# STM32F407 register map
File version: 1.2
CPU: CM4 r1p0, little endian, no MPU, no FPU, 4 interrupt priority bits
Registers are 32-bit, read-write, reset 0x0 unless marked. A register's access mark holds for its fields unless they carry their own. Offsets are from the block's base; [hi:lo] are bit positions; {n}, {i} and the like mark numbered series; 'fields as' and 'values as' point back to an identical list.

## FSMC — Flexible static memory controller
Base 0xA0000000
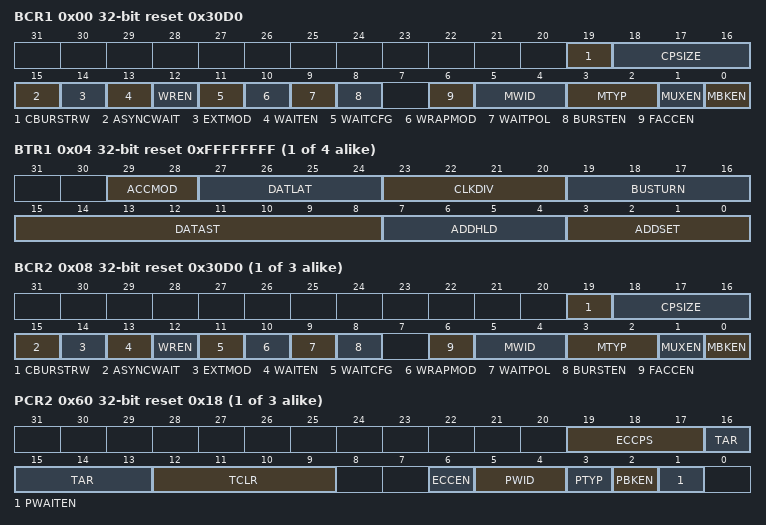
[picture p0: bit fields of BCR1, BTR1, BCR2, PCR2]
0x00 BCR1 reset 0x30D0 — SRAM/NOR-Flash chip-select control register 1
  [19] CBURSTRW
    1=Enabled (Write operations are performed in synchronous mode); 0=Disabled (Write operations are always performed in asynchronous mode)
  [18:16] CPSIZE — CRAM page size
    0=No burst split when crossing page boundary; 1=Bytes128 (128 bytes CRAM page size); 2=Bytes256 (256 bytes CRAM page size); 3=Bytes512 (512 bytes CRAM page size); 4=Bytes1024 (1024 bytes CRAM page size)
  [15] ASYNCWAIT
    0=Disabled (Wait signal not used in asynchronous mode); 1=Enabled (Wait signal used even in asynchronous mode)
  [14] EXTMOD
    0=Disabled (Values inside the FMC_BWTR are not taken into account); 1=Enabled (Values inside the FMC_BWTR are taken into account)
  [13] WAITEN
    0=Disabled (Values inside the FMC_BWTR are taken into account); 1=Enabled (NWAIT signal enabled)
  [12] WREN
    0=Disabled (Write operations disabled for the bank by the FMC); 1=Enabled (Write operations enabled for the bank by the FMC)
  [11] WAITCFG
    0=BeforeWaitState (NWAIT signal is active one data cycle before wait state); 1=DuringWaitState (NWAIT signal is active during wait state)
  [10] WRAPMOD
  [9] WAITPOL
    0=ActiveLow (NWAIT active low); 1=ActiveHigh (NWAIT active high)
  [8] BURSTEN
    0=Disabled (Burst mode disabled); 1=Enabled (Burst mode enabled)
  [6] FACCEN
    0=Disabled (Corresponding NOR Flash memory access is disabled); 1=Enabled (Corresponding NOR Flash memory access is enabled)
  [5:4] MWID
    0=Bits8 (Memory data bus width 8 bits); 1=Bits16 (Memory data bus width 16 bits); 2=Bits32 (Memory data bus width 32 bits)
  [3:2] MTYP
    0=SRAM (SRAM memory type); 1=PSRAM (PSRAM (CRAM) memory type); 2=Flash (NOR Flash/OneNAND Flash)
  [1] MUXEN
    0=Disabled (Address/Data non-multiplexed); 1=Enabled (Address/Data multiplexed on databus)
  [0] MBKEN
    0=Disabled (Corresponding memory bank is disabled); 1=Enabled (Corresponding memory bank is enabled)
0x04 BTR{i} (i=1..4; step 0x8) reset 0xFFFFFFFF — SRAM/NOR-Flash chip-select timing register 1
  [29:28] ACCMOD
    0=A (Access mode A); 1=B (Access mode B); 2=C (Access mode C); 3=D (Access mode D)
  [27:24] DATLAT
  [23:20] CLKDIV range 1..15
  [19:16] BUSTURN
  [15:8] DATAST range 1..255
  [7:4] ADDHLD range 1..15
  [3:0] ADDSET
0x08 BCR{i} (i=2..4; step 0x8) reset 0x30D0 — SRAM/NOR-Flash chip-select control register 2
  fields as BCR1
{0x20+0x20*i} PCR{i} (i=2..4) reset 0x18 — PC Card/NAND Flash control register 2
  [19:17] ECCPS
    0=Bytes256 (ECC page size 256 bytes); 1=Bytes512 (ECC page size 512 bytes); 2=Bytes1024 (ECC page size 1024 bytes); 3=Bytes2048 (ECC page size 2048 bytes); 4=Bytes4096 (ECC page size 4096 bytes); 5=Bytes8192 (ECC page size 8192 bytes)
  [16:13] TAR
  [12:9] TCLR
  [6] ECCEN
    0=Disabled (ECC logic is disabled and reset); 1=Enabled (ECC logic is enabled)
  [5:4] PWID
    0=Bits8 (External memory device width 8 bits); 1=Bits16 (External memory device width 16 bits)
  [3] PTYP
    1=NANDFlash
  [2] PBKEN
    values as BCR1.MBKEN
  [1] PWAITEN
    0=Disabled (Wait feature disabled); 1=Enabled (Wait feature enabled)
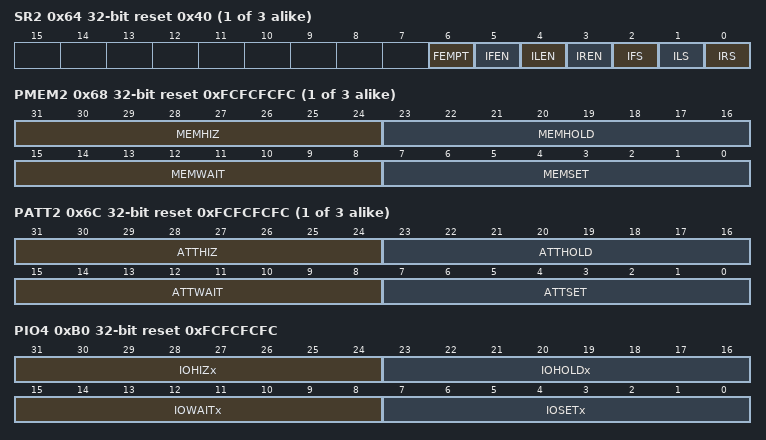
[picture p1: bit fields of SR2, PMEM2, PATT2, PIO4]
{0x24+0x20*i} SR{i} (i=2..4) access per field reset 0x40 — FIFO status and interrupt register 2
  [6] FEMPT ro
    0=NotEmpty (FIFO not empty); 1=Empty (FIFO empty)
  [5] IFEN rw
    0=Disabled (Interrupt falling edge detection request disabled); 1=Enabled (Interrupt falling edge detection request enabled)
  [4] ILEN rw
    0=Disabled (Interrupt high-level detection request disabled); 1=Enabled (Interrupt high-level detection request enabled)
  [3] IREN rw
    0=Disabled (Interrupt rising edge detection request disabled); 1=Enabled (Interrupt rising edge detection request enabled)
  [2] IFS rw
    0=DidNotOccur (Interrupt falling edge did not occur); 1=Occurred (Interrupt falling edge occurred)
  [1] ILS rw
    0=DidNotOccur (Interrupt high-level did not occur); 1=Occurred (Interrupt high-level occurred)
  [0] IRS rw
    0=DidNotOccur (Interrupt rising edge did not occur); 1=Occurred (Interrupt rising edge occurred)
{0x28+0x20*i} PMEM{i} reset 0xFCFCFCFC (i=2..4) — Common memory space timing register {i}
  [31:24] MEMHIZ range 0..254 — MEMHIZx
  [23:16] MEMHOLD range 1..254 — MEMHOLDx
  [15:8] MEMWAIT range 1..254 — MEMWAITx
  [7:0] MEMSET range 0..254 — MEMSETx
{0x2C+0x20*i} PATT{i} reset 0xFCFCFCFC (i=2..4) — Attribute memory space timing register {i}
  [31:24] ATTHIZ range 0..254 — ATTHIZx
  [23:16] ATTHOLD range 1..254 — ATTHOLDx
  [15:8] ATTWAIT range 1..254 — ATTWAITx
  [7:0] ATTSET range 0..254 — ATTSETx
0x74 ECCR2 ro — ECC result register 2
  [31:0] ECC — ECCx
0x94 ECCR3 ro — ECC result register 3
  [31:0] ECC — ECCx
0xB0 PIO4 reset 0xFCFCFCFC — I/O space timing register 4
  [31:24] IOHIZx, [23:16] IOHOLDx, [15:8] IOWAITx, [7:0] IOSETx
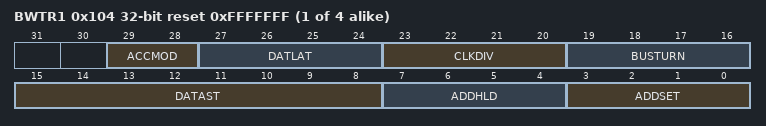
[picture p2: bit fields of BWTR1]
{0xFC+8i} BWTR{i} (i=1..4) reset 0xFFFFFFF — SRAM/NOR-Flash write timing registers 1
  [29:28] ACCMOD
    values as BTR{i}.ACCMOD
  [27:24] DATLAT
  [23:20] CLKDIV
  [19:16] BUSTURN — Bus turnaround phase duration
  [15:8] DATAST range 1..255
  [7:4] ADDHLD range 1..15
  [3:0] ADDSET
